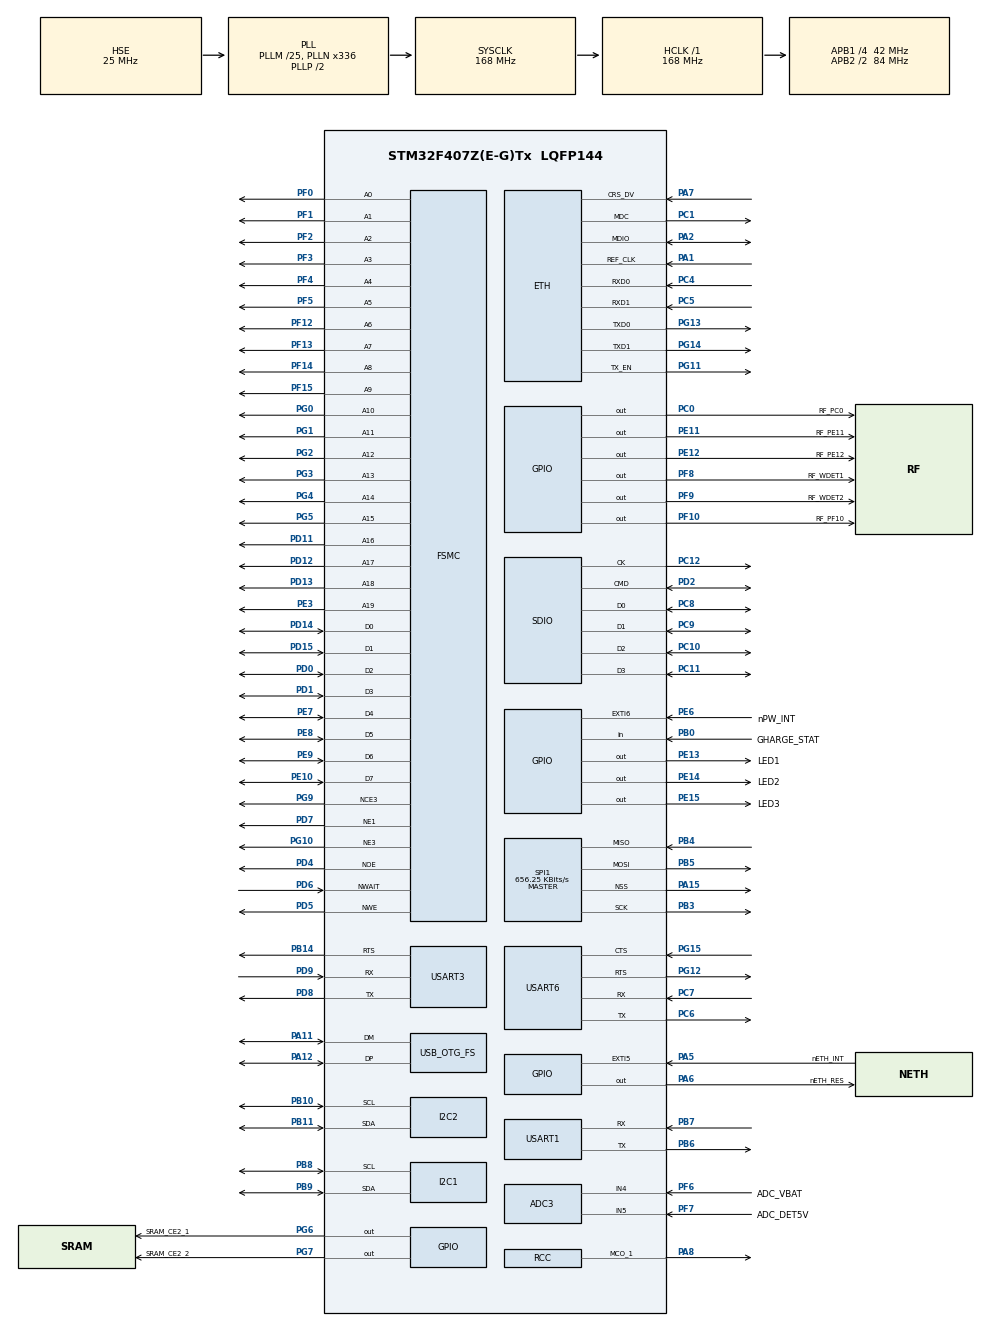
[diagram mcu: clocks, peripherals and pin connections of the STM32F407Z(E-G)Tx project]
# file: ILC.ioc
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ADC3.Channel-0\#ChannelRegularConversion=ADC_CHANNEL_4
ADC3.ClockPrescaler=ADC_CLOCK_SYNC_PCLK_DIV8
ADC3.NbrOfConversionFlag=1
ADC3.Rank-0\#ChannelRegularConversion=1
ADC3.SamplingTime-0\#ChannelRegularConversion=ADC_SAMPLETIME_3CYCLES
ETH.MACAddr=00\:80\:E1\:00\:00\:01
ETH.MediaInterface=ETH_MEDIA_INTERFACE_RMII
ETH.PhyAddress=0
FREERTOS.INCLUDE_pcTaskGetTaskName=1
FREERTOS.INCLUDE_uxTaskGetStackHighWaterMark=1
FREERTOS.Queues01=debug_TTqueue,5,uint16_t,0,Dynamic,NULL,NULL;WM_TTqueue,5,uint16_t,0,Dynamic,NULL,NULL;PW_TTqueue,5,uint16_t,0,Dynamic,NULL,NULL;CL_TTqueue,5,uint16_t,0,Dynamic,NULL,NULL
FREERTOS.Tasks01=debugTask,0,256,startDebugTask,Default,NULL,Dynamic,NULL,NULL;WM_task,-3,256,startWM_task,Default,NULL,Dynamic,NULL,NULL;PW_task,-3,256,startPW_task,Default,NULL,Dynamic,NULL,NULL;CL_task,-3,128,startCL_task,Default,NULL,Dynamic,NULL,NULL
FREERTOS.Timers01=SampleTimer,sampleTimerCall,osTimerPeriodic,Default,NULL,Dynamic,NULL
FREERTOS.configMINIMAL_STACK_SIZE=128
FREERTOS.configUSE_MALLOC_FAILED_HOOK=1
FREERTOS.configUSE_TIMERS=1
FSMC.NandBlockNbr1=1024
FSMC.NandBlockSize1=64
FSMC.NandPageSize1=2048
FSMC.NandPlaneNbr1=1
FSMC.NandPlaneSize1=1024
FSMC.NandSpareAreaSize1=125000000
FSMC.WriteOperation1=FSMC_WRITE_OPERATION_ENABLE
FSMC.WriteOperation2=FSMC_WRITE_OPERATION_ENABLE
I2C1.I2C_Mode=I2C_Fast
I2C2.I2C_Mode=I2C_Fast
LWIP.GATEWAY_ADDRESS=192.168.001.001
LWIP.IP_ADDRESS=192.168.001.050
LWIP.LWIP_DHCP=0
LWIP.LWIP_DNS=1
LWIP.LWIP_ICMP=1
LWIP.LWIP_PERF=1
LWIP.LWIP_SNTP=1
LWIP.LWIP_STATS=1
LWIP.MEMP_NUM_TCP_SEG=24
LWIP.NETMASK_ADDRESS=255.255.255.000
LWIP.TCP_MSS=460
LWIP.TCP_SND_BUF=1840
LWIP.TCP_WND=2048
LWIP.Version=v2.0.3_Cube
Mcu.Family=STM32F4
Mcu.Name=STM32F407Z(E-G)Tx
Mcu.Package=LQFP144
NVIC.ETH_IRQn=true\:5\:0\:false\:false\:true\:true\:false
NVIC.OTG_FS_IRQn=true\:5\:0\:false\:false\:true\:true\:false
NVIC.PriorityGroup=NVIC_PRIORITYGROUP_4
NVIC.TIM1_UP_TIM10_IRQn=true\:0\:0\:false\:false\:true\:false\:false
NVIC.TimeBase=TIM1_UP_TIM10_IRQn
NVIC.TimeBaseIP=TIM1
PA1.Mode=RMII
PA1.Signal=ETH_REF_CLK
PA11.Mode=Device_Only
PA11.Signal=USB_OTG_FS_DM
PA12.Mode=Device_Only
PA12.Signal=USB_OTG_FS_DP
PA13.Mode=Serial_Wire
PA13.Signal=SYS_JTMS-SWDIO
PA14.Mode=Serial_Wire
PA14.Signal=SYS_JTCK-SWCLK
PA15.Mode=NSS_Signal_Hard_Output
PA15.Signal=SPI1_NSS
PA2.Mode=RMII
PA2.Signal=ETH_MDIO
PA5.GPIO_Label=nETH_INT
PA5.GPIO_ModeDefaultEXTI=GPIO_MODE_IT_FALLING
PA5.GPIO_PuPd=GPIO_PULLDOWN
PA5.Signal=GPXTI5
PA6.GPIO_Label=nETH_RES
PA6.GPIO_PuPd=GPIO_PULLUP
PA6.GPIO_Speed=GPIO_SPEED_FREQ_LOW
PA6.PinState=GPIO_PIN_SET
PA6.Signal=GPIO_Output
PA7.Mode=RMII
PA7.Signal=ETH_CRS_DV
PA8.Mode=Clock-out-1
PA8.Signal=RCC_MCO_1
PB0.GPIO_Label=GHARGE_STAT
PB0.GPIO_PuPd=GPIO_PULLUP
PB0.Signal=GPIO_Input
PB10.Mode=I2C
PB10.Signal=I2C2_SCL
PB11.Mode=I2C
PB11.Signal=I2C2_SDA
PB14.Mode=RTS_Only
PB14.Signal=USART3_RTS
PB3.Mode=Full_Duplex_Master
PB3.Signal=SPI1_SCK
PB4.Mode=Full_Duplex_Master
PB4.Signal=SPI1_MISO
PB5.Mode=Full_Duplex_Master
PB5.Signal=SPI1_MOSI
PB6.Mode=Asynchronous
PB6.Signal=USART1_TX
PB7.Mode=Asynchronous
PB7.Signal=USART1_RX
PB8.Mode=I2C
PB8.Signal=I2C1_SCL
PB9.Mode=I2C
PB9.Signal=I2C1_SDA
PC0.GPIO_Label=RF_PC0
PC0.Signal=GPIO_Output
PC1.Mode=RMII
PC1.Signal=ETH_MDC
PC10.Mode=SD_4_bits_Wide_bus
PC10.Signal=SDIO_D2
PC11.Mode=SD_4_bits_Wide_bus
PC11.Signal=SDIO_D3
PC12.Mode=SD_4_bits_Wide_bus
PC12.Signal=SDIO_CK
PC14-OSC32_IN.Mode=LSE-External-Oscillator
PC14-OSC32_IN.Signal=RCC_OSC32_IN
PC15-OSC32_OUT.Mode=LSE-External-Oscillator
PC15-OSC32_OUT.Signal=RCC_OSC32_OUT
PC4.Mode=RMII
PC4.Signal=ETH_RXD0
PC5.Mode=RMII
PC5.Signal=ETH_RXD1
PC6.Mode=Asynchronous
PC6.Signal=USART6_TX
PC7.Mode=Asynchronous
PC7.Signal=USART6_RX
PC8.Mode=SD_4_bits_Wide_bus
PC8.Signal=SDIO_D0
PC9.Mode=SD_4_bits_Wide_bus
PC9.Signal=SDIO_D1
PD0.Signal=FSMC_D2_DA2
PD1.Signal=FSMC_D3_DA3
PD11.Signal=FSMC_A16_CLE
PD12.Signal=FSMC_A17_ALE
PD13.Signal=FSMC_A18
PD14.Signal=FSMC_D0_DA0
PD15.Signal=FSMC_D1_DA1
PD2.Mode=SD_4_bits_Wide_bus
PD2.Signal=SDIO_CMD
PD4.Signal=FSMC_NOE
PD5.Signal=FSMC_NWE
PD6.Signal=FSMC_NWAIT
PD7.Mode=NorPsramChipSelect1_1
PD7.Signal=FSMC_NE1
PD8.Mode=Asynchronous
PD8.Signal=USART3_TX
PD9.Mode=Asynchronous
PD9.Signal=USART3_RX
PE10.Signal=FSMC_D7_DA7
PE11.GPIO_Label=RF_PE11
PE11.Signal=GPIO_Output
PE12.GPIO_Label=RF_PE12
PE12.Signal=GPIO_Output
PE13.GPIO_Label=LED1
PE13.GPIO_PuPd=GPIO_PULLDOWN
PE13.Signal=GPIO_Output
PE14.GPIO_Label=LED2
PE14.GPIO_PuPd=GPIO_PULLDOWN
PE14.Signal=GPIO_Output
PE15.GPIO_Label=LED3
PE15.GPIO_PuPd=GPIO_PULLDOWN
PE15.Signal=GPIO_Output
PE3.Signal=FSMC_A19
PE6.GPIO_Label=nPW_INT
PE6.GPIO_ModeDefaultEXTI=GPIO_MODE_IT_FALLING
PE6.GPIO_PuPd=GPIO_PULLUP
PE6.Signal=GPXTI6
PE7.Signal=FSMC_D4_DA4
PE8.Signal=FSMC_D5_DA5
PE9.Signal=FSMC_D6_DA6
PF0.Signal=FSMC_A0
PF1.Signal=FSMC_A1
PF10.GPIO_Label=RF_PF10
PF10.GPIO_PuPd=GPIO_PULLDOWN
PF10.Signal=GPIO_Output
PF12.Signal=FSMC_A6
PF13.Signal=FSMC_A7
PF14.Signal=FSMC_A8
PF15.Signal=FSMC_A9
PF2.Signal=FSMC_A2
PF3.Signal=FSMC_A3
PF4.Signal=FSMC_A4
PF5.Signal=FSMC_A5
PF6.GPIO_Label=ADC_VBAT
PF6.Mode=IN4
PF6.Signal=ADC3_IN4
PF7.GPIO_Label=ADC_DET5V
PF7.Mode=IN5
PF7.Signal=ADC3_IN5
PF8.GPIO_Label=RF_WDET1
PF8.GPIO_PuPd=GPIO_PULLDOWN
PF8.Signal=GPIO_Output
PF9.GPIO_Label=RF_WDET2
PF9.GPIO_PuPd=GPIO_PULLDOWN
PF9.Signal=GPIO_Output
PG0.Signal=FSMC_A10
PG1.Signal=FSMC_A11
PG10.Mode=NorPsramChipSelect3_2
PG10.Signal=FSMC_NE3
PG11.Mode=RMII
PG11.Signal=ETH_TX_EN
PG12.Mode=CTS_RTS
PG12.Signal=USART6_RTS
PG13.Mode=RMII
PG13.Signal=ETH_TXD0
PG14.Mode=RMII
PG14.Signal=ETH_TXD1
PG15.Mode=CTS_RTS
PG15.Signal=USART6_CTS
PG2.Signal=FSMC_A12
PG3.Signal=FSMC_A13
PG4.Signal=FSMC_A14
PG5.Signal=FSMC_A15
PG6.GPIO_Label=SRAM_CE2_1
PG6.GPIO_PuPd=GPIO_PULLDOWN
PG6.Signal=GPIO_Output
PG7.GPIO_Label=SRAM_CE2_2
PG7.GPIO_PuPd=GPIO_PULLDOWN
PG7.Signal=GPIO_Output
PG9.Mode=NandChipSelect3_1
PG9.Signal=FSMC_NCE3
PH0-OSC_IN.Mode=HSE-External-Oscillator
PH0-OSC_IN.Signal=RCC_OSC_IN
PH1-OSC_OUT.Mode=HSE-External-Oscillator
PH1-OSC_OUT.Signal=RCC_OSC_OUT
ProjectManager.HeapSize=0x400
ProjectManager.StackSize=0x400
ProjectManager.TargetToolchain=EWARM
RCC.48MHZClocksFreq_Value=48000000
RCC.AHBFreq_Value=168000000
RCC.APB1CLKDivider=RCC_HCLK_DIV4
RCC.APB1Freq_Value=42000000
RCC.APB1TimFreq_Value=84000000
RCC.APB2CLKDivider=RCC_HCLK_DIV2
RCC.APB2Freq_Value=84000000
RCC.APB2TimFreq_Value=168000000
RCC.CortexFreq_Value=168000000
RCC.HCLKFreq_Value=168000000
RCC.HSE_Timout=200
RCC.HSE_VALUE=25000000
RCC.HSICalibrationValue=16
RCC.HSI_VALUE=16000000
RCC.PLLM=25
RCC.PLLN=336
RCC.PLLQ=7
RCC.RCC_MCO1Source=RCC_MCO1SOURCE_PLLCLK
RCC.SYSCLKFreq_VALUE=168000000
RCC.SYSCLKSource=RCC_SYSCLKSOURCE_PLLCLK
RCC.VCOOutputFreq_Value=336000000
SH.FSMC_A0.0=FSMC_A0,20b-a1
SH.FSMC_A0.1=FSMC_A0,20b-a2
SH.FSMC_A1.0=FSMC_A1,20b-a1
SH.FSMC_A1.1=FSMC_A1,20b-a2
SH.FSMC_A10.0=FSMC_A10,20b-a1
SH.FSMC_A10.1=FSMC_A10,20b-a2
SH.FSMC_A11.0=FSMC_A11,20b-a1
SH.FSMC_A11.1=FSMC_A11,20b-a2
SH.FSMC_A12.0=FSMC_A12,20b-a1
SH.FSMC_A12.1=FSMC_A12,20b-a2
SH.FSMC_A13.0=FSMC_A13,20b-a1
SH.FSMC_A13.1=FSMC_A13,20b-a2
SH.FSMC_A14.0=FSMC_A14,20b-a1
SH.FSMC_A14.1=FSMC_A14,20b-a2
SH.FSMC_A15.0=FSMC_A15,20b-a1
SH.FSMC_A15.1=FSMC_A15,20b-a2
SH.FSMC_A16_CLE.0=FSMC_A16,20b-a1
SH.FSMC_A16_CLE.1=FSMC_A16,20b-a2
SH.FSMC_A16_CLE.2=FSMC_CLE,8b-dmux1
SH.FSMC_A17_ALE.0=FSMC_A17,20b-a1
SH.FSMC_A17_ALE.1=FSMC_A17,20b-a2
SH.FSMC_A17_ALE.2=FSMC_ALE,8b-dmux1
SH.FSMC_A18.0=FSMC_A18,20b-a1
SH.FSMC_A18.1=FSMC_A18,20b-a2
SH.FSMC_A19.0=FSMC_A19,20b-a1
SH.FSMC_A19.1=FSMC_A19,20b-a2
SH.FSMC_A2.0=FSMC_A2,20b-a1
SH.FSMC_A2.1=FSMC_A2,20b-a2
SH.FSMC_A3.0=FSMC_A3,20b-a1
SH.FSMC_A3.1=FSMC_A3,20b-a2
SH.FSMC_A4.0=FSMC_A4,20b-a1
SH.FSMC_A4.1=FSMC_A4,20b-a2
SH.FSMC_A5.0=FSMC_A5,20b-a1
SH.FSMC_A5.1=FSMC_A5,20b-a2
SH.FSMC_A6.0=FSMC_A6,20b-a1
SH.FSMC_A6.1=FSMC_A6,20b-a2
SH.FSMC_A7.0=FSMC_A7,20b-a1
SH.FSMC_A7.1=FSMC_A7,20b-a2
SH.FSMC_A8.0=FSMC_A8,20b-a1
SH.FSMC_A8.1=FSMC_A8,20b-a2
SH.FSMC_A9.0=FSMC_A9,20b-a1
SH.FSMC_A9.1=FSMC_A9,20b-a2
SH.FSMC_D0_DA0.0=FSMC_D0,8b-d1
SH.FSMC_D0_DA0.1=FSMC_D0,8b-d2
SH.FSMC_D0_DA0.2=FSMC_D0,8b-dmux1
SH.FSMC_D1_DA1.0=FSMC_D1,8b-d1
SH.FSMC_D1_DA1.1=FSMC_D1,8b-d2
SH.FSMC_D1_DA1.2=FSMC_D1,8b-dmux1
SH.FSMC_D2_DA2.0=FSMC_D2,8b-d1
SH.FSMC_D2_DA2.1=FSMC_D2,8b-d2
SH.FSMC_D2_DA2.2=FSMC_D2,8b-dmux1
SH.FSMC_D3_DA3.0=FSMC_D3,8b-d1
SH.FSMC_D3_DA3.1=FSMC_D3,8b-d2
SH.FSMC_D3_DA3.2=FSMC_D3,8b-dmux1
SH.FSMC_D4_DA4.0=FSMC_D4,8b-d1
SH.FSMC_D4_DA4.1=FSMC_D4,8b-d2
SH.FSMC_D4_DA4.2=FSMC_D4,8b-dmux1
SH.FSMC_D5_DA5.0=FSMC_D5,8b-d1
SH.FSMC_D5_DA5.1=FSMC_D5,8b-d2
SH.FSMC_D5_DA5.2=FSMC_D5,8b-dmux1
SH.FSMC_D6_DA6.0=FSMC_D6,8b-d1
SH.FSMC_D6_DA6.1=FSMC_D6,8b-d2
SH.FSMC_D6_DA6.2=FSMC_D6,8b-dmux1
SH.FSMC_D7_DA7.0=FSMC_D7,8b-d1
SH.FSMC_D7_DA7.1=FSMC_D7,8b-d2
SH.FSMC_D7_DA7.2=FSMC_D7,8b-dmux1
SH.FSMC_NOE.0=FSMC_NOE,Sram1
SH.FSMC_NOE.1=FSMC_NOE,Sram2
SH.FSMC_NOE.2=FSMC_NOE,8b-dmux1
SH.FSMC_NWAIT.0=FSMC_NWAIT,AsynchronousWait1
SH.FSMC_NWAIT.1=FSMC_NWAIT,AsynchronousWait2
SH.FSMC_NWAIT.2=FSMC_NWAIT,Wait1
SH.FSMC_NWE.0=FSMC_NWE,Sram1
SH.FSMC_NWE.1=FSMC_NWE,Sram2
SH.FSMC_NWE.2=FSMC_NWE,8b-dmux1
SPI1.BaudRatePrescaler=SPI_BAUDRATEPRESCALER_128
SPI1.CalculateBaudRate=656.25 KBits/s
SPI1.Direction=SPI_DIRECTION_2LINES
SPI1.Mode=SPI_MODE_MASTER
SPI1.VirtualNSS=VM_NSSHARD
SPI1.VirtualType=VM_MASTER
USART1.VirtualMode=VM_ASYNC
USART3.VirtualMode=VM_ASYNC
USART6.VirtualMode=VM_ASYNC
USB_DEVICE.APP_RX_DATA_SIZE-CDC_FS=512
USB_DEVICE.APP_TX_DATA_SIZE-CDC_FS=512
USB_DEVICE.CLASS_NAME_FS=CDC
USB_DEVICE.MANUFACTURER_STRING-CDC_FS=INSYTE
USB_DEVICE.PRODUCT_STRING_CDC_FS=Counter
USB_DEVICE.SERIALNUMBER_STRING_CDC_FS=00000000001B
USB_DEVICE.VirtualMode-CDC_FS=Cdc
USB_DEVICE.VirtualModeFS=Cdc_FS
USB_OTG_FS.VirtualMode=Device_Only
VP_CRC_VS_CRC.Mode=CRC_Activate
VP_FATFS_VS_Generic.Mode=User_defined
VP_FATFS_VS_SDIO.Mode=SDIO
VP_FREERTOS_VS_ENABLE.Mode=Enabled
VP_LWIP_VS_Enabled.Mode=Enabled
VP_RTC_VS_RTC_Activate.Mode=RTC_Enabled
VP_RTC_VS_RTC_Calendar.Mode=RTC_Calendar
VP_SYS_VS_tim1.Mode=TIM1
VP_USB_DEVICE_VS_USB_DEVICE_CDC_FS.Mode=CDC_FS
board=ILC

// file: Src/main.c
#include "main.h"
#include "stm32f4xx_hal.h"
#include "cmsis_os.h"
#include "fatfs.h"
#include "lwip.h"
#include "usb_device.h"

/* USER CODE BEGIN Includes */
#include "devMQTT.h"
#include "DevCTRL.h"
#include "usbd_cdc_if.h"
#include "PCA9555.h"
#include "V9203.h"
#include "Clock.h"
#include "dns.h"
#include "EMS_protocol.h"
#include "FW_update.h"
#include "TASK_script.h"
#include "USB_port.h"
#include "USB_ctrl.h"

/* USER CODE END Includes */

SD_HandleTypeDef hsd;
DMA_HandleTypeDef hdma_sdio_rx;
DMA_HandleTypeDef hdma_sdio_tx;

ADC_HandleTypeDef hadc3;

CRC_HandleTypeDef hcrc;

I2C_HandleTypeDef hi2c1;
I2C_HandleTypeDef hi2c2;

RTC_HandleTypeDef hrtc;

IWDG_HandleTypeDef hiwdg;

SD_HandleTypeDef hsd;

SPI_HandleTypeDef hspi1;

UART_HandleTypeDef huart1;
UART_HandleTypeDef huart3;
UART_HandleTypeDef huart6;

SRAM_HandleTypeDef hsram1;
SRAM_HandleTypeDef hsram2;
NAND_HandleTypeDef hnand1;

osThreadId debugTaskHandle;
osTimerId SampleTimerHandle;

osMessageQId debug_TTqueueHandle;
osMessageQId EMS_TTqueueHandle;
osMessageQId Modem_TTqueueHandle;

/* USER CODE BEGIN PV */
/* Private variables ---------------------------------------------------------*/

/* USER CODE END PV */

void SystemClock_Config(void);
static void MX_GPIO_Init(void);
static void MX_DMA_Init(void);
static void MX_ADC3_Init(void);
static void MX_FSMC_Init(void);
static void MX_I2C1_Init(void);
static void MX_I2C2_Init(void);
static void MX_SDIO_SD_Init(void);
static void MX_SPI1_Init(void);
static void MX_USART1_UART_Init(void);
static void MX_USART3_UART_Init(void);
static void MX_USART6_UART_Init(void);
static void MX_CRC_Init(void);
static void MX_RTC_Init(void);
static void MX_IWDG_Init(void);
void startDebugTask(void const * argument);
void sampleTimerCall(void const * argument);

/* USER CODE BEGIN PFP */
/* Private function prototypes -----------------------------------------------*/

/* USER CODE END PFP */

/* USER CODE BEGIN 0 */

SemaphoreHandle_t muxNAND;
SemaphoreHandle_t muxSRAM1;
SemaphoreHandle_t muxSRAM2;
SemaphoreHandle_t muxUSB;
SemaphoreHandle_t muxV9203;
SemaphoreHandle_t muxData;
SemaphoreHandle_t muxSD;

/* USER CODE END 0 */

 int main(void)
{
  /* USER CODE BEGIN 1 */

  SCB->VTOR = FW_IMAGE_START_ADDRESS;

  /* USER CODE END 1 */

  /* MCU Configuration----------------------------------------------------------*/

  /* Reset of all peripherals, Initializes the Flash interface and the Systick. */
  HAL_Init();

  /* Configure the system clock */
  SystemClock_Config();

  /* Initialize all configured peripherals */
  MX_GPIO_Init();
  MX_DMA_Init();
  MX_ADC3_Init();
  MX_FSMC_Init();
  MX_I2C1_Init();
  MX_I2C2_Init();
  MX_SDIO_SD_Init();
  MX_SPI1_Init();
  MX_USART1_UART_Init();
  MX_USART3_UART_Init();
  MX_USART6_UART_Init();
  MX_CRC_Init();
  MX_RTC_Init();
  MX_IWDG_Init();
  /* USER CODE BEGIN 2 */

  __enable_irq();

  /* USER CODE END 2 */

  /* USER CODE BEGIN RTOS_MUTEX */
  muxNAND = xSemaphoreCreateMutex();
  muxSRAM1 = xSemaphoreCreateMutex();
  muxSRAM2 = xSemaphoreCreateMutex();
  muxUSB = xSemaphoreCreateMutex();
  muxV9203 = xSemaphoreCreateMutex();
  muxData = xSemaphoreCreateMutex();
  muxSD = xSemaphoreCreateMutex();

  /* Create the timer(s) */
  osTimerDef(SampleTimer, sampleTimerCall);
  SampleTimerHandle = osTimerCreate(osTimer(SampleTimer), osTimerPeriodic, NULL);

  /* definition and creation of debugTask */
  osThreadDef(debugTask, startDebugTask, osPriorityNormal, 0, 256);
  debugTaskHandle = osThreadCreate(osThread(debugTask), NULL);

  /* Create the queue(s) */
  osMessageQDef(debug_TTqueue, 5, uint16_t);
  debug_TTqueueHandle = osMessageCreate(osMessageQ(debug_TTqueue), NULL);

  osMessageQDef(EMS_TTqueue, 5, uint16_t);
  EMS_TTqueueHandle = osMessageCreate(osMessageQ(EMS_TTqueue), NULL);

  osMessageQDef(Modem_TTqueue, 5, uint16_t);
  Modem_TTqueueHandle = osMessageCreate(osMessageQ(Modem_TTqueue), NULL);

  /* Start scheduler */
  osKernelStart();

  while (1)
  {

  }
}

void SystemClock_Config(void)
{

  RCC_OscInitTypeDef RCC_OscInitStruct;
  RCC_ClkInitTypeDef RCC_ClkInitStruct;
  RCC_PeriphCLKInitTypeDef PeriphClkInitStruct;

    /**Configure the main internal regulator output voltage
    */
  __HAL_RCC_PWR_CLK_ENABLE();

  __HAL_PWR_VOLTAGESCALING_CONFIG(PWR_REGULATOR_VOLTAGE_SCALE1);

    /**Initializes the CPU, AHB and APB busses clocks
    */
  RCC_OscInitStruct.OscillatorType = RCC_OSCILLATORTYPE_LSI|RCC_OSCILLATORTYPE_HSE;
  RCC_OscInitStruct.HSEState = RCC_HSE_ON;
  RCC_OscInitStruct.LSIState = RCC_LSI_ON;
  RCC_OscInitStruct.PLL.PLLState = RCC_PLL_ON;
  RCC_OscInitStruct.PLL.PLLSource = RCC_PLLSOURCE_HSE;
  RCC_OscInitStruct.PLL.PLLM = 25;
  RCC_OscInitStruct.PLL.PLLN = 336;
  RCC_OscInitStruct.PLL.PLLP = RCC_PLLP_DIV2;
  RCC_OscInitStruct.PLL.PLLQ = 7;
  if (HAL_RCC_OscConfig(&RCC_OscInitStruct) != HAL_OK)
  {
    _Error_Handler(__FILE__, __LINE__);
  }

    /**Initializes the CPU, AHB and APB busses clocks
    */
  RCC_ClkInitStruct.ClockType = RCC_CLOCKTYPE_HCLK|RCC_CLOCKTYPE_SYSCLK
                              |RCC_CLOCKTYPE_PCLK1|RCC_CLOCKTYPE_PCLK2;
  RCC_ClkInitStruct.SYSCLKSource = RCC_SYSCLKSOURCE_PLLCLK;
  RCC_ClkInitStruct.AHBCLKDivider = RCC_SYSCLK_DIV1;
  RCC_ClkInitStruct.APB1CLKDivider = RCC_HCLK_DIV4;
  RCC_ClkInitStruct.APB2CLKDivider = RCC_HCLK_DIV2;

  if (HAL_RCC_ClockConfig(&RCC_ClkInitStruct, FLASH_LATENCY_5) != HAL_OK)
  {
    _Error_Handler(__FILE__, __LINE__);
  }

  PeriphClkInitStruct.PeriphClockSelection = RCC_PERIPHCLK_RTC;
  PeriphClkInitStruct.RTCClockSelection = RCC_RTCCLKSOURCE_LSI;
  if (HAL_RCCEx_PeriphCLKConfig(&PeriphClkInitStruct) != HAL_OK)
  {
    _Error_Handler(__FILE__, __LINE__);
  }

  HAL_RCC_MCOConfig(RCC_MCO1, RCC_MCO1SOURCE_PLLCLK, RCC_MCODIV_1);

    /**Configure the Systick interrupt time
    */
  HAL_SYSTICK_Config(HAL_RCC_GetHCLKFreq()/1000);

    /**Configure the Systick
    */
  HAL_SYSTICK_CLKSourceConfig(SYSTICK_CLKSOURCE_HCLK);

  /* SysTick_IRQn interrupt configuration */
  HAL_NVIC_SetPriority(SysTick_IRQn, 15, 0);
}

/* IWDG init function */
static void MX_IWDG_Init(void)
{

  hiwdg.Instance = IWDG;
  hiwdg.Init.Prescaler = IWDG_PRESCALER_8;
  hiwdg.Init.Reload = 4095;  //4 sec
  if (HAL_IWDG_Init(&hiwdg) != HAL_OK)
  {
    _Error_Handler(__FILE__, __LINE__);
  }

}

static void MX_DMA_Init(void)
{
  /* DMA controller clock enable */
  __HAL_RCC_DMA2_CLK_ENABLE();

  /* DMA interrupt init */
  /* DMA2_Stream3_IRQn interrupt configuration */
  HAL_NVIC_SetPriority(DMA2_Stream3_IRQn, 5, 0);
  HAL_NVIC_EnableIRQ(DMA2_Stream3_IRQn);
  /* DMA2_Stream6_IRQn interrupt configuration */
  HAL_NVIC_SetPriority(DMA2_Stream6_IRQn, 5, 0);
  HAL_NVIC_EnableIRQ(DMA2_Stream6_IRQn);
}

/* ADC3 init function */
static void MX_ADC3_Init(void)
{

  ADC_ChannelConfTypeDef sConfig;

    /**Configure the global features of the ADC (Clock, Resolution, Data Alignment and number of conversion)
    */
  hadc3.Instance = ADC3;
  hadc3.Init.ClockPrescaler = ADC_CLOCK_SYNC_PCLK_DIV8;
  hadc3.Init.Resolution = ADC_RESOLUTION_12B;
  hadc3.Init.ScanConvMode = DISABLE;
  hadc3.Init.ContinuousConvMode = DISABLE;
  hadc3.Init.DiscontinuousConvMode = DISABLE;
  hadc3.Init.ExternalTrigConvEdge = ADC_EXTERNALTRIGCONVEDGE_NONE;
  hadc3.Init.ExternalTrigConv = ADC_SOFTWARE_START;
  hadc3.Init.DataAlign = ADC_DATAALIGN_RIGHT;
  hadc3.Init.NbrOfConversion = 1;
  hadc3.Init.DMAContinuousRequests = DISABLE;
  hadc3.Init.EOCSelection = ADC_EOC_SINGLE_CONV;
  if (HAL_ADC_Init(&hadc3) != HAL_OK)
  {
    _Error_Handler(__FILE__, __LINE__);
  }

    /**Configure for the selected ADC regular channel its corresponding rank in the sequencer and its sample time.
    */
  sConfig.Channel = ADC_CHANNEL_4;
  sConfig.Rank = 1;
  sConfig.SamplingTime = ADC_SAMPLETIME_3CYCLES;
  if (HAL_ADC_ConfigChannel(&hadc3, &sConfig) != HAL_OK)
  {
    _Error_Handler(__FILE__, __LINE__);
  }

}

/* CRC init function */
static void MX_CRC_Init(void)
{

  hcrc.Instance = CRC;
  if (HAL_CRC_Init(&hcrc) != HAL_OK)
  {
    _Error_Handler(__FILE__, __LINE__);
  }

}

/* I2C1 init function */
static void MX_I2C1_Init(void)
{

  hi2c1.Instance = I2C1;
  hi2c1.Init.ClockSpeed = 500000;
  hi2c1.Init.DutyCycle = I2C_DUTYCYCLE_2;
  hi2c1.Init.OwnAddress1 = 0;
  hi2c1.Init.AddressingMode = I2C_ADDRESSINGMODE_7BIT;
  hi2c1.Init.DualAddressMode = I2C_DUALADDRESS_DISABLE;
  hi2c1.Init.OwnAddress2 = 0;
  hi2c1.Init.GeneralCallMode = I2C_GENERALCALL_DISABLE;
  hi2c1.Init.NoStretchMode = I2C_NOSTRETCH_DISABLE;
  if (HAL_I2C_Init(&hi2c1) != HAL_OK)
  {
    _Error_Handler(__FILE__, __LINE__);
  }

}

/* I2C2 init function */
static void MX_I2C2_Init(void)
{

  hi2c2.Instance = I2C2;
  hi2c2.Init.ClockSpeed = 400000;
  hi2c2.Init.DutyCycle = I2C_DUTYCYCLE_2;
  hi2c2.Init.OwnAddress1 = 0;
  hi2c2.Init.AddressingMode = I2C_ADDRESSINGMODE_7BIT;
  hi2c2.Init.DualAddressMode = I2C_DUALADDRESS_DISABLE;
  hi2c2.Init.OwnAddress2 = 0;
  hi2c2.Init.GeneralCallMode = I2C_GENERALCALL_DISABLE;
  hi2c2.Init.NoStretchMode = I2C_NOSTRETCH_DISABLE;
  if (HAL_I2C_Init(&hi2c2) != HAL_OK)
  {
    _Error_Handler(__FILE__, __LINE__);
  }

}

/* RTC init function */
static void MX_RTC_Init(void)
{

  RTC_TimeTypeDef sTime;
  RTC_DateTypeDef sDate;

    /**Initialize RTC Only
    */
  hrtc.Instance = RTC;
if(HAL_RTCEx_BKUPRead(&hrtc, RTC_BKP_DR0) != 0x32F2){
  hrtc.Init.HourFormat = RTC_HOURFORMAT_24;
  hrtc.Init.AsynchPrediv = 127;
  hrtc.Init.SynchPrediv = 255;
  hrtc.Init.OutPut = RTC_OUTPUT_DISABLE;
  hrtc.Init.OutPutPolarity = RTC_OUTPUT_POLARITY_HIGH;
  hrtc.Init.OutPutType = RTC_OUTPUT_TYPE_OPENDRAIN;
  if (HAL_RTC_Init(&hrtc) != HAL_OK)
  {
    _Error_Handler(__FILE__, __LINE__);
  }

    /**Initialize RTC and set the Time and Date
    */
  sTime.Hours = 0x0;
  sTime.Minutes = 0x0;
  sTime.Seconds = 0x0;
  sTime.DayLightSaving = RTC_DAYLIGHTSAVING_NONE;
  sTime.StoreOperation = RTC_STOREOPERATION_RESET;
  if (HAL_RTC_SetTime(&hrtc, &sTime, RTC_FORMAT_BCD) != HAL_OK)
  {
    _Error_Handler(__FILE__, __LINE__);
  }

  sDate.WeekDay = RTC_WEEKDAY_MONDAY;
  sDate.Month = RTC_MONTH_JANUARY;
  sDate.Date = 0x1;
  sDate.Year = 0x0;

  if (HAL_RTC_SetDate(&hrtc, &sDate, RTC_FORMAT_BCD) != HAL_OK)
  {
    _Error_Handler(__FILE__, __LINE__);
  }

    HAL_RTCEx_BKUPWrite(&hrtc,RTC_BKP_DR0,0x32F2);
  }

}

/* SDIO init function */
static void MX_SDIO_SD_Init(void)
{
  hsd.Instance = SDIO;
  hsd.Init.ClockEdge = SDIO_CLOCK_EDGE_RISING;
  hsd.Init.ClockBypass = SDIO_CLOCK_BYPASS_DISABLE;
  hsd.Init.ClockPowerSave = SDIO_CLOCK_POWER_SAVE_DISABLE;
  hsd.Init.BusWide = SDIO_BUS_WIDE_1B;
  hsd.Init.HardwareFlowControl = SDIO_HARDWARE_FLOW_CONTROL_DISABLE;
  hsd.Init.ClockDiv = 0;

}

/* SPI1 init function */
static void MX_SPI1_Init(void)
{

  /* SPI1 parameter configuration*/
  hspi1.Instance = SPI1;
  hspi1.Init.Mode = SPI_MODE_MASTER;
  hspi1.Init.Direction = SPI_DIRECTION_2LINES;
  hspi1.Init.DataSize = SPI_DATASIZE_8BIT;
  hspi1.Init.CLKPolarity = SPI_POLARITY_HIGH;
  hspi1.Init.CLKPhase = SPI_PHASE_2EDGE;
  hspi1.Init.NSS = SPI_NSS_SOFT;
  hspi1.Init.BaudRatePrescaler = SPI_BAUDRATEPRESCALER_256;
  hspi1.Init.FirstBit = SPI_FIRSTBIT_MSB;
  hspi1.Init.TIMode = SPI_TIMODE_DISABLE;
  hspi1.Init.CRCCalculation = SPI_CRCCALCULATION_DISABLE;
  hspi1.Init.CRCPolynomial = 10;
  if (HAL_SPI_Init(&hspi1) != HAL_OK)
  {
    _Error_Handler(__FILE__, __LINE__);
  }

}

/* USART1 init function */
static void MX_USART1_UART_Init(void)
{

  huart1.Instance = USART1;
  huart1.Init.BaudRate = 115200;
  huart1.Init.WordLength = UART_WORDLENGTH_8B;
  huart1.Init.StopBits = UART_STOPBITS_1;
  huart1.Init.Parity = UART_PARITY_NONE;
  huart1.Init.Mode = UART_MODE_TX_RX;
  huart1.Init.HwFlowCtl = UART_HWCONTROL_NONE;
  huart1.Init.OverSampling = UART_OVERSAMPLING_16;
  if (HAL_UART_Init(&huart1) != HAL_OK)
  {
    _Error_Handler(__FILE__, __LINE__);
  }

}

/* USART3 init function */
static void MX_USART3_UART_Init(void)
{

  huart3.Instance = USART3;
  huart3.Init.BaudRate = 115200;
  huart3.Init.WordLength = UART_WORDLENGTH_8B;
  huart3.Init.StopBits = UART_STOPBITS_1;
  huart3.Init.Parity = UART_PARITY_NONE;
  huart3.Init.Mode = UART_MODE_TX_RX;
  huart3.Init.HwFlowCtl = UART_HWCONTROL_RTS;
  huart3.Init.OverSampling = UART_OVERSAMPLING_16;
  if (HAL_UART_Init(&huart3) != HAL_OK)
  {
    _Error_Handler(__FILE__, __LINE__);
  }

}

/* USART6 init function */
static void MX_USART6_UART_Init(void)
{

  huart6.Instance = USART6;
  huart6.Init.BaudRate = 115200;
  huart6.Init.WordLength = UART_WORDLENGTH_8B;
  huart6.Init.StopBits = UART_STOPBITS_1;
  huart6.Init.Parity = UART_PARITY_NONE;
  huart6.Init.Mode = UART_MODE_TX_RX;
  huart6.Init.HwFlowCtl = UART_HWCONTROL_RTS_CTS;
  huart6.Init.OverSampling = UART_OVERSAMPLING_16;
  if (HAL_UART_Init(&huart6) != HAL_OK)
  {
    _Error_Handler(__FILE__, __LINE__);
  }

}

/** Configure pins as
        * Analog
        * Input
        * Output
        * EVENT_OUT
        * EXTI
     PA8   ------> RCC_MCO_1
*/
static void MX_GPIO_Init(void)
{

  GPIO_InitTypeDef GPIO_InitStruct;

  /* GPIO Ports Clock Enable */
  __HAL_RCC_GPIOE_CLK_ENABLE();
  __HAL_RCC_GPIOC_CLK_ENABLE();
  __HAL_RCC_GPIOF_CLK_ENABLE();
  __HAL_RCC_GPIOH_CLK_ENABLE();
  __HAL_RCC_GPIOA_CLK_ENABLE();
  __HAL_RCC_GPIOB_CLK_ENABLE();
  __HAL_RCC_GPIOG_CLK_ENABLE();
  __HAL_RCC_GPIOD_CLK_ENABLE();

  /*Configure GPIO pin Output Level */
  HAL_GPIO_WritePin(GPIOF, RF_WDET1_Pin|RF_WDET2_Pin|RF_PF10_Pin, GPIO_PIN_RESET);

  /*Configure GPIO pin Output Level */
  HAL_GPIO_WritePin(RF_PC0_GPIO_Port, RF_PC0_Pin, GPIO_PIN_RESET);

  /*Configure GPIO pin Output Level */
  HAL_GPIO_WritePin(nETH_RES_GPIO_Port, nETH_RES_Pin, GPIO_PIN_SET);

  /*Configure GPIO pin Output Level */
  HAL_GPIO_WritePin(GPIOE, RF_PE11_Pin|RF_PE12_Pin|LED1_Pin|LED2_Pin
                          |LED3_Pin, GPIO_PIN_RESET);

  /*Configure GPIO pin Output Level */
  HAL_GPIO_WritePin(GPIOG, SRAM_CE2_1_Pin|SRAM_CE2_2_Pin, GPIO_PIN_RESET);

  /*Configure GPIO pin : nPW_INT_Pin */
  GPIO_InitStruct.Pin = nPW_INT_Pin;
  GPIO_InitStruct.Mode = GPIO_MODE_IT_FALLING;
  GPIO_InitStruct.Pull = GPIO_PULLUP;
  HAL_GPIO_Init(nPW_INT_GPIO_Port, &GPIO_InitStruct);

  /*Configure GPIO pins : RF_WDET1_Pin RF_WDET2_Pin RF_PF10_Pin */
  GPIO_InitStruct.Pin = RF_WDET1_Pin|RF_WDET2_Pin|RF_PF10_Pin;
  GPIO_InitStruct.Mode = GPIO_MODE_OUTPUT_PP;
  GPIO_InitStruct.Pull = GPIO_PULLDOWN;
  GPIO_InitStruct.Speed = GPIO_SPEED_FREQ_LOW;
  HAL_GPIO_Init(GPIOF, &GPIO_InitStruct);

  /*Configure GPIO pin : RF_PC0_Pin */
  GPIO_InitStruct.Pin = RF_PC0_Pin;
  GPIO_InitStruct.Mode = GPIO_MODE_OUTPUT_PP;
  GPIO_InitStruct.Pull = GPIO_NOPULL;
  GPIO_InitStruct.Speed = GPIO_SPEED_FREQ_LOW;
  HAL_GPIO_Init(RF_PC0_GPIO_Port, &GPIO_InitStruct);

  /*Configure GPIO pin : nETH_INT_Pin */
  GPIO_InitStruct.Pin = nETH_INT_Pin;
  GPIO_InitStruct.Mode = GPIO_MODE_IT_FALLING;
  GPIO_InitStruct.Pull = GPIO_PULLDOWN;
  HAL_GPIO_Init(nETH_INT_GPIO_Port, &GPIO_InitStruct);

  /*Configure GPIO pin : nETH_RES_Pin */
  GPIO_InitStruct.Pin = nETH_RES_Pin;
  GPIO_InitStruct.Mode = GPIO_MODE_OUTPUT_PP;
  GPIO_InitStruct.Pull = GPIO_PULLUP;
  GPIO_InitStruct.Speed = GPIO_SPEED_FREQ_LOW;
  HAL_GPIO_Init(nETH_RES_GPIO_Port, &GPIO_InitStruct);

  /*Configure GPIO pin : GHARGE_STAT_Pin */
  GPIO_InitStruct.Pin = GHARGE_STAT_Pin;
  GPIO_InitStruct.Mode = GPIO_MODE_INPUT;
  GPIO_InitStruct.Pull = GPIO_PULLUP;
  HAL_GPIO_Init(GHARGE_STAT_GPIO_Port, &GPIO_InitStruct);

  /*Configure GPIO pins : RF_PE11_Pin RF_PE12_Pin */
  GPIO_InitStruct.Pin = RF_PE11_Pin|RF_PE12_Pin;
  GPIO_InitStruct.Mode = GPIO_MODE_OUTPUT_PP;
  GPIO_InitStruct.Pull = GPIO_NOPULL;
  GPIO_InitStruct.Speed = GPIO_SPEED_FREQ_LOW;
  HAL_GPIO_Init(GPIOE, &GPIO_InitStruct);

  /*Configure GPIO pins : LED1_Pin LED2_Pin LED3_Pin */
  GPIO_InitStruct.Pin = LED1_Pin|LED2_Pin|LED3_Pin;
  GPIO_InitStruct.Mode = GPIO_MODE_OUTPUT_PP;
  GPIO_InitStruct.Pull = GPIO_PULLDOWN;
  GPIO_InitStruct.Speed = GPIO_SPEED_FREQ_LOW;
  HAL_GPIO_Init(GPIOE, &GPIO_InitStruct);

  /*Configure GPIO pins : SRAM_CE2_1_Pin SRAM_CE2_2_Pin */
  GPIO_InitStruct.Pin = SRAM_CE2_1_Pin|SRAM_CE2_2_Pin;
  GPIO_InitStruct.Mode = GPIO_MODE_OUTPUT_PP;
  GPIO_InitStruct.Pull = GPIO_PULLDOWN;
  GPIO_InitStruct.Speed = GPIO_SPEED_FREQ_LOW;
  HAL_GPIO_Init(GPIOG, &GPIO_InitStruct);

  /*Configure GPIO pin : PA8 */
  GPIO_InitStruct.Pin = GPIO_PIN_8;
  GPIO_InitStruct.Mode = GPIO_MODE_AF_PP;
  GPIO_InitStruct.Pull = GPIO_NOPULL;
  GPIO_InitStruct.Speed = GPIO_SPEED_FREQ_LOW;
  GPIO_InitStruct.Alternate = GPIO_AF0_MCO;
  HAL_GPIO_Init(GPIOA, &GPIO_InitStruct);

  /*Configure GPIO pins : PW_CS_GPIO_Pin */
  GPIO_InitStruct.Pin = PW_CS_Pin;
  GPIO_InitStruct.Mode = GPIO_MODE_OUTPUT_PP;
  GPIO_InitStruct.Pull = GPIO_PULLDOWN;
  GPIO_InitStruct.Speed = GPIO_SPEED_FREQ_HIGH;
  HAL_GPIO_Init(PW_CS_GPIO_Port, &GPIO_InitStruct);

  HAL_GPIO_WritePin(PW_CS_GPIO_Port, PW_CS_Pin, GPIO_PIN_RESET); //CS SPI
}

/* FSMC initialization function */
static void MX_FSMC_Init(void)
{
  FSMC_NORSRAM_TimingTypeDef Timing;
  FSMC_NAND_PCC_TimingTypeDef ComSpaceTiming;
  FSMC_NAND_PCC_TimingTypeDef AttSpaceTiming;

  /** Perform the SRAM1 memory initialization sequence
  */
  hsram1.Instance = FSMC_NORSRAM_DEVICE;
  hsram1.Extended = FSMC_NORSRAM_EXTENDED_DEVICE;
  /* hsram1.Init */
  hsram1.Init.NSBank = FSMC_NORSRAM_BANK1;
  hsram1.Init.DataAddressMux = FSMC_DATA_ADDRESS_MUX_DISABLE;
  hsram1.Init.MemoryType = FSMC_MEMORY_TYPE_SRAM;
  hsram1.Init.MemoryDataWidth = FSMC_NORSRAM_MEM_BUS_WIDTH_8;
  hsram1.Init.BurstAccessMode = FSMC_BURST_ACCESS_MODE_DISABLE;
  hsram1.Init.WaitSignalPolarity = FSMC_WAIT_SIGNAL_POLARITY_LOW;
  hsram1.Init.WrapMode = FSMC_WRAP_MODE_DISABLE;
  hsram1.Init.WaitSignalActive = FSMC_WAIT_TIMING_BEFORE_WS;
  hsram1.Init.WriteOperation = FSMC_WRITE_OPERATION_ENABLE;
  hsram1.Init.WaitSignal = FSMC_WAIT_SIGNAL_DISABLE;
  hsram1.Init.ExtendedMode = FSMC_EXTENDED_MODE_DISABLE;
  hsram1.Init.AsynchronousWait = FSMC_ASYNCHRONOUS_WAIT_ENABLE;
  hsram1.Init.WriteBurst = FSMC_WRITE_BURST_DISABLE;
  hsram1.Init.PageSize = FSMC_PAGE_SIZE_NONE;
  /* Timing */
  Timing.AddressSetupTime = 15;
  Timing.AddressHoldTime = 15;
  Timing.DataSetupTime = 255;
  Timing.BusTurnAroundDuration = 15;
  Timing.CLKDivision = 16;
  Timing.DataLatency = 17;
  Timing.AccessMode = FSMC_ACCESS_MODE_A;
  /* ExtTiming */

  if (HAL_SRAM_Init(&hsram1, &Timing, NULL) != HAL_OK)
  {
    _Error_Handler(__FILE__, __LINE__);
  }

  /** Perform the SRAM2 memory initialization sequence
  */
  hsram2.Instance = FSMC_NORSRAM_DEVICE;
  hsram2.Extended = FSMC_NORSRAM_EXTENDED_DEVICE;
  /* hsram2.Init */
  hsram2.Init.NSBank = FSMC_NORSRAM_BANK3;
  hsram2.Init.DataAddressMux = FSMC_DATA_ADDRESS_MUX_DISABLE;
  hsram2.Init.MemoryType = FSMC_MEMORY_TYPE_SRAM;
  hsram2.Init.MemoryDataWidth = FSMC_NORSRAM_MEM_BUS_WIDTH_8;
  hsram2.Init.BurstAccessMode = FSMC_BURST_ACCESS_MODE_DISABLE;
  hsram2.Init.WaitSignalPolarity = FSMC_WAIT_SIGNAL_POLARITY_LOW;
  hsram2.Init.WrapMode = FSMC_WRAP_MODE_DISABLE;
  hsram2.Init.WaitSignalActive = FSMC_WAIT_TIMING_BEFORE_WS;
  hsram2.Init.WriteOperation = FSMC_WRITE_OPERATION_ENABLE;
  hsram2.Init.WaitSignal = FSMC_WAIT_SIGNAL_DISABLE;
  hsram2.Init.ExtendedMode = FSMC_EXTENDED_MODE_DISABLE;
  hsram2.Init.AsynchronousWait = FSMC_ASYNCHRONOUS_WAIT_ENABLE;
  hsram2.Init.WriteBurst = FSMC_WRITE_BURST_DISABLE;
  hsram2.Init.PageSize = FSMC_PAGE_SIZE_NONE;
  /* Timing */
  Timing.AddressSetupTime = 15;
  Timing.AddressHoldTime = 15;
  Timing.DataSetupTime = 255;
  Timing.BusTurnAroundDuration = 15;
  Timing.CLKDivision = 16;
  Timing.DataLatency = 17;
  Timing.AccessMode = FSMC_ACCESS_MODE_A;
  /* ExtTiming */

  if (HAL_SRAM_Init(&hsram2, &Timing, NULL) != HAL_OK)
  {
    _Error_Handler(__FILE__, __LINE__);
  }

  /** Perform the NAND1 memory initialization sequence
  */
  hnand1.Instance = FSMC_NAND_DEVICE;
  /* hnand1.Init */
  hnand1.Init.NandBank = FSMC_NAND_BANK3;
  hnand1.Init.Waitfeature = FSMC_NAND_PCC_WAIT_FEATURE_ENABLE;
  hnand1.Init.MemoryDataWidth = FSMC_NAND_PCC_MEM_BUS_WIDTH_8;
  hnand1.Init.EccComputation = FSMC_NAND_ECC_DISABLE;
  hnand1.Init.ECCPageSize = FSMC_NAND_ECC_PAGE_SIZE_2048BYTE;
  hnand1.Init.TCLRSetupTime = 0;
  hnand1.Init.TARSetupTime = 0;
  /* hnand1.Config */
  hnand1.Config.PageSize = 2048;
  hnand1.Config.SpareAreaSize = 128;
  hnand1.Config.BlockSize = 64;
  hnand1.Config.BlockNbr = 1024;
  hnand1.Config.PlaneNbr = 1;
  hnand1.Config.PlaneSize = 1024;
  hnand1.Config.ExtraCommandEnable = DISABLE;
  /* ComSpaceTiming */
  ComSpaceTiming.SetupTime = 252;
  ComSpaceTiming.WaitSetupTime = 252;
  ComSpaceTiming.HoldSetupTime = 252;
  ComSpaceTiming.HiZSetupTime = 252;
  /* AttSpaceTiming */
  AttSpaceTiming.SetupTime = 1;
  AttSpaceTiming.WaitSetupTime = 3;
  AttSpaceTiming.HoldSetupTime = 2;
  AttSpaceTiming.HiZSetupTime = 1;

  if (HAL_NAND_Init(&hnand1, &ComSpaceTiming, &AttSpaceTiming) != HAL_OK)
  {
    _Error_Handler(__FILE__, __LINE__);
  }

}

/* USER CODE BEGIN 4 */

  FRESULT FATF_res;
  FATFS FATF_Obj;
  FIL fileDebug;

/* USER CODE END 4 */

/* startDebugTask function */
void startDebugTask(void const * argument)
{
  /* init code for USB_DEVICE */
  MX_USB_DEVICE_Init();

  /* init code for FATFS */
  MX_FATFS_Init();

   /* USER CODE BEGIN 5 */
  DC_init(&debug_TTqueueHandle);

  V9203_init(&hspi1, &DC_set.EMS_channelEn, &DC_state.V9203_channelsActive, DC_calibr.channel_cal);

  /* init code for LWIP */
  MX_LWIP_Init(DC_set.net_dev_ip_addr, DC_set.net_mask, DC_set.net_gw_ip_addr, DC_set.net_DHCP_en);

  if (DC_set.net_DHCP_en == 1)
  {
    vTaskDelay(1000);

    uint8_t ip[4];
    if (MX_LWIP_getIP(ip))
    {
      DC_debug_ipAdrrOut("# DHCP enable, IP: ", ip);
    }
  }else{
    DC_debug_ipAdrrOut("# Static IP: ", DC_set.net_dev_ip_addr);
  }

  //Set led status
  stateState = LED_PROC_OK;

  //USB
  USBP_init();
  USBC_init(osPriorityNormal);

  //DNS init
  ip4_addr_t ipaddr;
  IP4_ADDR(&ipaddr, DC_set.serverDNS[0], DC_set.serverDNS[1], DC_set.serverDNS[2], DC_set.serverDNS[3]);
  dns_setserver(0, &ipaddr);
  dns_init();
  DC_debugOut("# DNS init OK\r\n");

  CL_init(); //Init clock

  USBP_mode = USBP_MODE_CMD;

  //Start sample timer
  osTimerStart(SampleTimerHandle, 1000);

  //Init EMS
  EMS_init();

  //Инициализация задачи
  TASK_script_init(0);

  /* USER CODE BEGIN 5 */
  /* Infinite loop */
  for(;;)
  {
    osDelay(1000);
  }

  /* USER CODE END 5 */
}

/* sampleTimerCall function */
void sampleTimerCall(void const * argument)
{
  dns_tmr();

  MX_link_sample(); //Link sample function

  if (DC_state.statFlags.ethLink == 1)
  linkState = LED_PROC_OK;
    else
  linkState = LED_PROC_ERROR;

  //Reload watchDog
  DC_reloadDog();
}

void HAL_TIM_PeriodElapsedCallback(TIM_HandleTypeDef *htim)
{
  if (htim->Instance == TIM1) {
    HAL_IncTick();
  }
}

void _Error_Handler(char *file, int line)
{
  while(1)
  {
  }
}

/************************ (C) COPYRIGHT STMicroelectronics *****END OF FILE****/

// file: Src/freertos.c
/**
  ******************************************************************************
  * File Name          : freertos.c
  * Description        : Code for freertos applications
  ******************************************************************************
  * This notice applies to any and all portions of this file
  * that are not between comment pairs USER CODE BEGIN and
  * USER CODE END. Other portions of this file, whether
  * inserted by the user or by software development tools
  * are owned by their respective copyright owners.
  *
  * Copyright (c) 2018 STMicroelectronics International N.V.
  * All rights reserved.
  *
  * Redistribution and use in source and binary forms, with or without
  * modification, are permitted, provided that the following conditions are met:
  *
  * 1. Redistribution of source code must retain the above copyright notice,
  *    this list of conditions and the following disclaimer.
  * 2. Redistributions in binary form must reproduce the above copyright notice,
  *    this list of conditions and the following disclaimer in the documentation
  *    and/or other materials provided with the distribution.
  * 3. Neither the name of STMicroelectronics nor the names of other
  *    contributors to this software may be used to endorse or promote products
  *    derived from this software without specific written permission.
  * 4. This software, including modifications and/or derivative works of this
  *    software, must execute solely and exclusively on microcontroller or
  *    microprocessor devices manufactured by or for STMicroelectronics.
  * 5. Redistribution and use of this software other than as permitted under
  *    this license is void and will automatically terminate your rights under
  *    this license.
  *
  * THIS SOFTWARE IS PROVIDED BY STMICROELECTRONICS AND CONTRIBUTORS "AS IS"
  * AND ANY EXPRESS, IMPLIED OR STATUTORY WARRANTIES, INCLUDING, BUT NOT
  * LIMITED TO, THE IMPLIED WARRANTIES OF MERCHANTABILITY, FITNESS FOR A
  * PARTICULAR PURPOSE AND NON-INFRINGEMENT OF THIRD PARTY INTELLECTUAL PROPERTY
  * RIGHTS ARE DISCLAIMED TO THE FULLEST EXTENT PERMITTED BY LAW. IN NO EVENT
  * SHALL STMICROELECTRONICS OR CONTRIBUTORS BE LIABLE FOR ANY DIRECT, INDIRECT,
  * INCIDENTAL, SPECIAL, EXEMPLARY, OR CONSEQUENTIAL DAMAGES (INCLUDING, BUT NOT
  * LIMITED TO, PROCUREMENT OF SUBSTITUTE GOODS OR SERVICES; LOSS OF USE, DATA,
  * OR PROFITS; OR BUSINESS INTERRUPTION) HOWEVER CAUSED AND ON ANY THEORY OF
  * LIABILITY, WHETHER IN CONTRACT, STRICT LIABILITY, OR TORT (INCLUDING
  * NEGLIGENCE OR OTHERWISE) ARISING IN ANY WAY OUT OF THE USE OF THIS SOFTWARE,
  * EVEN IF ADVISED OF THE POSSIBILITY OF SUCH DAMAGE.
  *
  ******************************************************************************
  */

#include "FreeRTOS.h"
#include "task.h"

/* Hook prototypes */
void vApplicationMallocFailedHook(void);

/* USER CODE BEGIN 5 */
__weak void vApplicationMallocFailedHook(void)
{
   /* vApplicationMallocFailedHook() will only be called if
   configUSE_MALLOC_FAILED_HOOK is set to 1 in FreeRTOSConfig.h. It is a hook
   function that will get called if a call to pvPortMalloc() fails.
   pvPortMalloc() is called internally by the kernel whenever a task, queue,
   timer or semaphore is created. It is also called by various parts of the
   demo application. If heap_1.c or heap_2.c are used, then the size of the
   heap available to pvPortMalloc() is defined by configTOTAL_HEAP_SIZE in
   FreeRTOSConfig.h, and the xPortGetFreeHeapSize() API function can be used
   to query the size of free heap space that remains (although it does not
   provide information on how the remaining heap might be fragmented). */
}
/* USER CODE END 5 */

/************************ (C) COPYRIGHT STMicroelectronics *****END OF FILE****/
